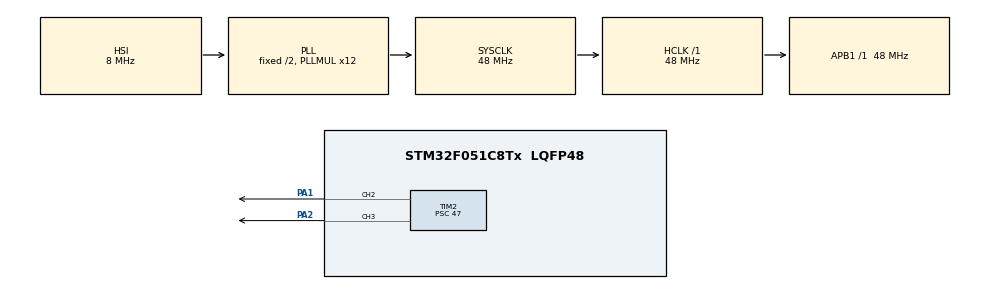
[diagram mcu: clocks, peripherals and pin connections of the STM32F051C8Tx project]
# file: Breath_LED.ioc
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Mcu.Family=STM32F0
Mcu.Name=STM32F051C8Tx
Mcu.Package=LQFP48
PA1.Signal=S_TIM2_CH2
PA2.Signal=S_TIM2_CH3
ProjectManager.TargetToolchain=MDK-ARM V5
RCC.AHBFreq_Value=48000000
RCC.APB1Freq_Value=48000000
RCC.APB1TimFreq_Value=48000000
RCC.HCLKFreq_Value=48000000
RCC.PLLMUL=RCC_PLL_MUL12
RCC.SYSCLKFreq_VALUE=48000000
RCC.SYSCLKSource=RCC_SYSCLKSOURCE_PLLCLK
SH.S_TIM2_CH2.0=TIM2_CH2,PWM Generation2 CH2
SH.S_TIM2_CH3.0=TIM2_CH3,PWM Generation3 CH3
TIM2.Channel-PWM\ Generation2\ CH2=TIM_CHANNEL_2
TIM2.Channel-PWM\ Generation3\ CH3=TIM_CHANNEL_3
TIM2.Period=999
TIM2.Prescaler=47
TIM2.Pulse-PWM\ Generation2\ CH2=800
TIM2.Pulse-PWM\ Generation3\ CH3=800
VP_TIM2_VS_ClockSourceINT.Mode=Internal
board=Breath_LED

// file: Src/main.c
/**
  ******************************************************************************
  * File Name          : main.c
  * Description        : Main program body
  ******************************************************************************
  *
  * COPYRIGHT(c) 2016 STMicroelectronics
  *
  * Redistribution and use in source and binary forms, with or without modification,
  * are permitted provided that the following conditions are met:
  *   1. Redistributions of source code must retain the above copyright notice,
  *      this list of conditions and the following disclaimer.
  *   2. Redistributions in binary form must reproduce the above copyright notice,
  *      this list of conditions and the following disclaimer in the documentation
  *      and/or other materials provided with the distribution.
  *   3. Neither the name of STMicroelectronics nor the names of its contributors
  *      may be used to endorse or promote products derived from this software
  *      without specific prior written permission.
  *
  * THIS SOFTWARE IS PROVIDED BY THE COPYRIGHT HOLDERS AND CONTRIBUTORS "AS IS"
  * AND ANY EXPRESS OR IMPLIED WARRANTIES, INCLUDING, BUT NOT LIMITED TO, THE
  * IMPLIED WARRANTIES OF MERCHANTABILITY AND FITNESS FOR A PARTICULAR PURPOSE ARE
  * DISCLAIMED. IN NO EVENT SHALL THE COPYRIGHT HOLDER OR CONTRIBUTORS BE LIABLE
  * FOR ANY DIRECT, INDIRECT, INCIDENTAL, SPECIAL, EXEMPLARY, OR CONSEQUENTIAL
  * DAMAGES (INCLUDING, BUT NOT LIMITED TO, PROCUREMENT OF SUBSTITUTE GOODS OR
  * SERVICES; LOSS OF USE, DATA, OR PROFITS; OR BUSINESS INTERRUPTION) HOWEVER
  * CAUSED AND ON ANY THEORY OF LIABILITY, WHETHER IN CONTRACT, STRICT LIABILITY,
  * OR TORT (INCLUDING NEGLIGENCE OR OTHERWISE) ARISING IN ANY WAY OUT OF THE USE
  * OF THIS SOFTWARE, EVEN IF ADVISED OF THE POSSIBILITY OF SUCH DAMAGE.
  *
  ******************************************************************************
  */
#include "stm32f0xx_hal.h"

TIM_HandleTypeDef htim2;

/* USER CODE BEGIN PV */
/* Private variables ---------------------------------------------------------*/

/* USER CODE END PV */

void SystemClock_Config(void);
static void MX_GPIO_Init(void);
static void MX_TIM2_Init(void);

/* USER CODE BEGIN PFP */
/* Private function prototypes -----------------------------------------------*/

/* USER CODE END PFP */

/* USER CODE BEGIN 0 */

void delay(uint16_t nCount)
{
    for(; nCount != 0; nCount--)
    { uint16_t i;
        for(i=0; i<10988; i++);
    }
}

/* USER CODE END 0 */

int main(void)
{

  /* USER CODE BEGIN 1 */
  uint16_t PWM_NUM=0;

  /* USER CODE END 1 */

  /* MCU Configuration----------------------------------------------------------*/

  /* Reset of all peripherals, Initializes the Flash interface and the Systick. */
  HAL_Init();

  /* Configure the system clock */
  SystemClock_Config();

  /* Initialize all configured peripherals */
  MX_GPIO_Init();
  MX_TIM2_Init();

     HAL_TIM_PWM_Start(&htim2,TIM_CHANNEL_2);
  // HAL_TIM_PWM_Start(&htim2,TIM_CHANNEL_3);

  /* Infinite loop */
  /* USER CODE BEGIN WHILE */
  while (1)
  {
     TIM2->CCR2=550;
     TIM2->CCR3=80;

       TIM2->CCR3=90;
     //  TIM2->CCR2=500;
    // delay(2000);

//
       TIM2->CCR3=250;
       TIM2->CCR2=0;
        delay(2000);

           TIM2->CCR3=0;
   //    TIM2->CCR2=500;
    //    delay(2000);
  /* USER CODE END WHILE */

  }

}

/** System Clock Configuration
*/
void SystemClock_Config(void)
{

  RCC_OscInitTypeDef RCC_OscInitStruct;
  RCC_ClkInitTypeDef RCC_ClkInitStruct;

  RCC_OscInitStruct.OscillatorType = RCC_OSCILLATORTYPE_HSI;
  RCC_OscInitStruct.HSIState = RCC_HSI_ON;
  RCC_OscInitStruct.HSICalibrationValue = 16;
  RCC_OscInitStruct.PLL.PLLState = RCC_PLL_ON;
  RCC_OscInitStruct.PLL.PLLSource = RCC_PLLSOURCE_HSI;
  RCC_OscInitStruct.PLL.PLLMUL = RCC_PLL_MUL12;
  RCC_OscInitStruct.PLL.PREDIV = RCC_PREDIV_DIV1;
  HAL_RCC_OscConfig(&RCC_OscInitStruct);

  RCC_ClkInitStruct.ClockType = RCC_CLOCKTYPE_SYSCLK;
  RCC_ClkInitStruct.SYSCLKSource = RCC_SYSCLKSOURCE_PLLCLK;
  RCC_ClkInitStruct.AHBCLKDivider = RCC_SYSCLK_DIV1;
  RCC_ClkInitStruct.APB1CLKDivider = RCC_HCLK_DIV1;
  HAL_RCC_ClockConfig(&RCC_ClkInitStruct, FLASH_LATENCY_1);

  HAL_SYSTICK_Config(HAL_RCC_GetHCLKFreq()/1000);

  HAL_SYSTICK_CLKSourceConfig(SYSTICK_CLKSOURCE_HCLK);

  /* SysTick_IRQn interrupt configuration */
  HAL_NVIC_SetPriority(SysTick_IRQn, 0, 0);
}

/* TIM2 init function */
void MX_TIM2_Init(void)
{

  TIM_ClockConfigTypeDef sClockSourceConfig;
  TIM_MasterConfigTypeDef sMasterConfig;
  TIM_OC_InitTypeDef sConfigOC;

  htim2.Instance = TIM2;
  htim2.Init.Prescaler = 47;
  htim2.Init.CounterMode = TIM_COUNTERMODE_UP;
  htim2.Init.Period = 999;
  htim2.Init.ClockDivision = TIM_CLOCKDIVISION_DIV1;
  HAL_TIM_Base_Init(&htim2);

  sClockSourceConfig.ClockSource = TIM_CLOCKSOURCE_INTERNAL;
  HAL_TIM_ConfigClockSource(&htim2, &sClockSourceConfig);

  HAL_TIM_PWM_Init(&htim2);

  sMasterConfig.MasterOutputTrigger = TIM_TRGO_RESET;
  sMasterConfig.MasterSlaveMode = TIM_MASTERSLAVEMODE_DISABLE;
  HAL_TIMEx_MasterConfigSynchronization(&htim2, &sMasterConfig);

  sConfigOC.OCMode = TIM_OCMODE_PWM1;
  sConfigOC.Pulse = 0;
  sConfigOC.OCPolarity = TIM_OCPOLARITY_HIGH;
  sConfigOC.OCFastMode = TIM_OCFAST_DISABLE;
  HAL_TIM_PWM_ConfigChannel(&htim2, &sConfigOC, TIM_CHANNEL_2);

  HAL_TIM_PWM_ConfigChannel(&htim2, &sConfigOC, TIM_CHANNEL_3);

}

/** Pinout Configuration
*/
void MX_GPIO_Init(void)
{

  /* GPIO Ports Clock Enable */
  __GPIOA_CLK_ENABLE();

}

/************************ (C) COPYRIGHT STMicroelectronics *****END OF FILE****/
